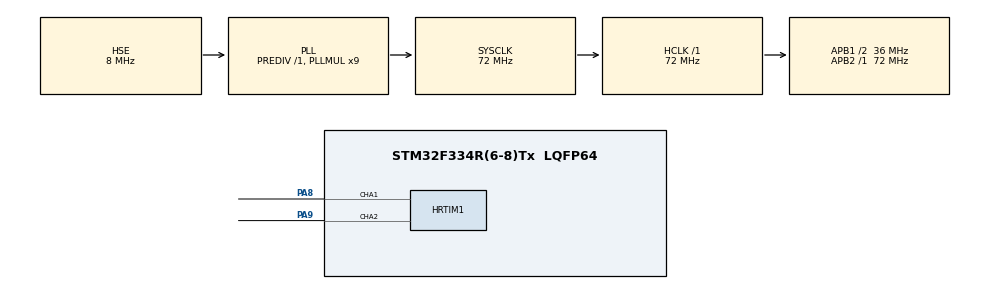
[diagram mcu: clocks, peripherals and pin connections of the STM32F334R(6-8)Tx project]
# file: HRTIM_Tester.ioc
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HRTIM1.CompareUnit1-Output_TA1TA2=HRTIM_COMPAREUNIT_1
HRTIM1.CompareValue1-Output_TA1TA2=576
HRTIM1.DeadTimeInsertion-Output_TA1TA2=HRTIM_TIMDEADTIMEINSERTION_ENABLED
HRTIM1.NumberResetSource1-Output_TA1TA2=1
HRTIM1.NumberSetSource1-Output_TA1TA2=1
HRTIM1.Periode_TA=1152
HRTIM1.PreloadEnable-Output_TA1TA2=HRTIM_PRELOAD_ENABLED
HRTIM1.RepetitionUpdate-Output_TA1TA2=HRTIM_UPDATEONREPETITION_ENABLED
HRTIM1.ResetOutput1_Source1-Output_TA1TA2=HRTIM_OUTPUTRESET_TIMCMP1
HRTIM1.SetOutput1_Source1-Output_TA1TA2=HRTIM_OUTPUTSET_TIMPER
Mcu.Family=STM32F3
Mcu.Name=STM32F334R(6-8)Tx
Mcu.Package=LQFP64
NVIC.PriorityGroup=NVIC_PRIORITYGROUP_4
PA13.Mode=Serial_Wire
PA13.Signal=SYS_JTMS-SWDIO
PA14.Mode=Serial_Wire
PA14.Signal=SYS_JTCK-SWCLK
PA8.Mode=Output_TA1TA2
PA8.Signal=HRTIM1_CHA1
PA9.Mode=Output_TA1TA2
PA9.Signal=HRTIM1_CHA2
PF0\ /\ OSC_IN.Mode=HSE-External-Oscillator
PF0\ /\ OSC_IN.Signal=RCC_OSC_IN
PF1\ /\ OSC_OUT.Mode=HSE-External-Oscillator
PF1\ /\ OSC_OUT.Signal=RCC_OSC_OUT
ProjectManager.HeapSize=0x200
ProjectManager.StackSize=0x400
ProjectManager.TargetToolchain=Makefile
RCC.AHBFreq_Value=72000000
RCC.APB1CLKDivider=RCC_HCLK_DIV2
RCC.APB1Freq_Value=36000000
RCC.APB1TimFreq_Value=72000000
RCC.APB2Freq_Value=72000000
RCC.APB2TimFreq_Value=72000000
RCC.CortexFreq_Value=72000000
RCC.HCLKFreq_Value=72000000
RCC.HRTIMSelection=RCC_HRTIM1CLK_PLLCLK
RCC.HSE_VALUE=8000000
RCC.HSI_VALUE=8000000
RCC.LSE_VALUE=32768
RCC.PLLMUL=RCC_PLL_MUL9
RCC.PLLSourceVirtual=RCC_PLLSOURCE_HSE
RCC.SYSCLKFreq_VALUE=72000000
RCC.SYSCLKSourceVirtual=RCC_SYSCLKSOURCE_PLLCLK
board=custom

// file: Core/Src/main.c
/* USER CODE BEGIN Header */
/**
 ******************************************************************************
 * @file           : main.c
 * @brief          : Main program body
 ******************************************************************************
 * @attention
 *
 * Copyright (c) 2024 STMicroelectronics.
 * All rights reserved.
 *
 * This software is licensed under terms that can be found in the LICENSE file
 * in the root directory of this software component.
 * If no LICENSE file comes with this software, it is provided AS-IS.
 *
 ******************************************************************************
 */
/* USER CODE END Header */
#include "main.h"
#include "gpio.h"
#include "hrtim.h"

void SystemClock_Config(void);

int main(void) {

  /* MCU Configuration--------------------------------------------------------*/

  /* Reset of all peripherals, Initializes the Flash interface and the Systick.
   */
  HAL_Init();

  /* Configure the system clock */
  SystemClock_Config();

  /* Initialize all configured peripherals */
  MX_GPIO_Init();
  MX_HRTIM1_Init();
  /* USER CODE BEGIN 2 */

  // Start HRTIM
  HAL_HRTIM_WaveformOutputStart(&hhrtim1, HRTIM_OUTPUT_TA1 | HRTIM_OUTPUT_TA2);
  HAL_HRTIM_WaveformCounterStart(&hhrtim1, HRTIM_TIMERID_TIMER_A);

  /*
    uint16_t compare = 100; // 0 ~ 1152

    HRTIM_CompareCfgTypeDef conf;

    conf.CompareValue = 576;
    HAL_HRTIM_WaveformCompareConfig(&hhrtim1, HRTIM_TIMERINDEX_TIMER_A,
    HRTIM_COMPAREUNIT_1, &conf);
  */

  /* USER CODE END 2 */

  /* Infinite loop */
  /* USER CODE BEGIN WHILE */
  while (1) {
    /*
    // Set period
    for (; compare < 1100; compare+=10) {

      // Set period
      conf.CompareValue = compare;
      HAL_HRTIM_WaveformCompareConfig(&hhrtim1, HRTIM_TIMERINDEX_TIMER_A,
    HRTIM_COMPAREUNIT_1, &conf);
      //conf.CompareValue = 1152 - compare;
      //HAL_HRTIM_WaveformCompareConfig(&hhrtim1, HRTIM_TIMERINDEX_TIMER_A,
    HRTIM_COMPAREUNIT_2, &conf);

      HAL_Delay(10);
    }

    // Set period
    for (; compare > 150; compare-=10) {

      // Set period
      conf.CompareValue = compare;
      HAL_HRTIM_WaveformCompareConfig(&hhrtim1, HRTIM_TIMERINDEX_TIMER_A,
    HRTIM_COMPAREUNIT_1, &conf);
      //conf.CompareValue = 1152 - compare;
      //HAL_HRTIM_WaveformCompareConfig(&hhrtim1, HRTIM_TIMERINDEX_TIMER_A,
    HRTIM_COMPAREUNIT_2, &conf);

      HAL_Delay(10);
    }
    */

    /* USER CODE END WHILE */

  }
}

void SystemClock_Config(void) {
  RCC_OscInitTypeDef RCC_OscInitStruct = {0};
  RCC_ClkInitTypeDef RCC_ClkInitStruct = {0};
  RCC_PeriphCLKInitTypeDef PeriphClkInit = {0};

  /** Initializes the RCC Oscillators according to the specified parameters
   * in the RCC_OscInitTypeDef structure.
   */
  RCC_OscInitStruct.OscillatorType = RCC_OSCILLATORTYPE_HSE;
  RCC_OscInitStruct.HSEState = RCC_HSE_ON;
  RCC_OscInitStruct.HSEPredivValue = RCC_HSE_PREDIV_DIV1;
  RCC_OscInitStruct.HSIState = RCC_HSI_ON;
  RCC_OscInitStruct.PLL.PLLState = RCC_PLL_ON;
  RCC_OscInitStruct.PLL.PLLSource = RCC_PLLSOURCE_HSE;
  RCC_OscInitStruct.PLL.PLLMUL = RCC_PLL_MUL9;
  if (HAL_RCC_OscConfig(&RCC_OscInitStruct) != HAL_OK) {
    Error_Handler();
  }

  /** Initializes the CPU, AHB and APB buses clocks
   */
  RCC_ClkInitStruct.ClockType = RCC_CLOCKTYPE_HCLK | RCC_CLOCKTYPE_SYSCLK |
                                RCC_CLOCKTYPE_PCLK1 | RCC_CLOCKTYPE_PCLK2;
  RCC_ClkInitStruct.SYSCLKSource = RCC_SYSCLKSOURCE_PLLCLK;
  RCC_ClkInitStruct.AHBCLKDivider = RCC_SYSCLK_DIV1;
  RCC_ClkInitStruct.APB1CLKDivider = RCC_HCLK_DIV2;
  RCC_ClkInitStruct.APB2CLKDivider = RCC_HCLK_DIV1;

  if (HAL_RCC_ClockConfig(&RCC_ClkInitStruct, FLASH_LATENCY_2) != HAL_OK) {
    Error_Handler();
  }
  PeriphClkInit.PeriphClockSelection = RCC_PERIPHCLK_HRTIM1;
  PeriphClkInit.Hrtim1ClockSelection = RCC_HRTIM1CLK_PLLCLK;
  if (HAL_RCCEx_PeriphCLKConfig(&PeriphClkInit) != HAL_OK) {
    Error_Handler();
  }
}

void Error_Handler(void) {
  __disable_irq();
  while (1) {
  }
}

#ifdef USE_FULL_ASSERT
/**
 * @brief  Reports the name of the source file and the source line number
 *         where the assert_param error has occurred.
 * @param  file: pointer to the source file name
 * @param  line: assert_param error line source number
 * @retval None
 */
void assert_failed(uint8_t *file, uint32_t line) {
  /* USER CODE BEGIN 6 */
  /* User can add his own implementation to report the file name and line
     number, ex: printf("Wrong parameters value: file %s on line %d\r\n", file,
     line) */
  /* USER CODE END 6 */
}
#endif /* USE_FULL_ASSERT */
